# STM32WB30CEU6A register map
File version: 1.0
Registers are 32-bit, access not given, reset 0x0 unless marked. A register's access mark holds for its fields unless they carry their own. Offsets are from the block's base; [hi:lo] are bit positions; {n}, {i} and the like mark numbered series.

## GPIOE
Base 0x48001000
0x00 MODER
  [9:8] MODE4
0x04 OTYPER
  [4] OT4
0x08 OSPEEDR
  [9:8] OSPEED4
0x0C PUPDR
  [9:8] PUPD4
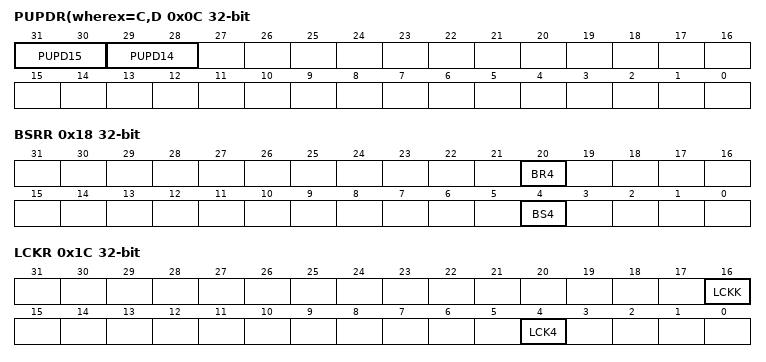
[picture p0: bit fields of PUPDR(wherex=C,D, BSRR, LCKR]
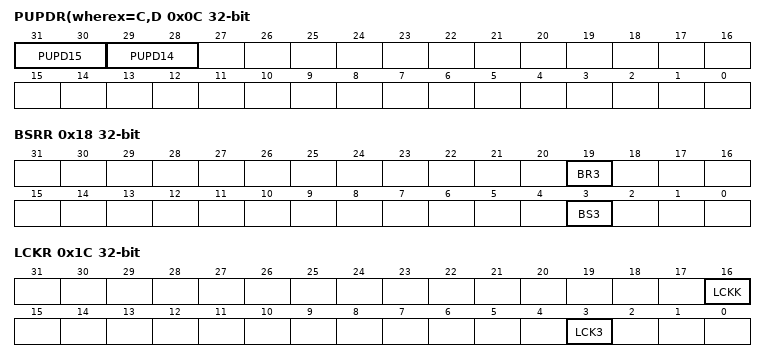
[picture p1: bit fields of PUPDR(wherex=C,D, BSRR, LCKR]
0x0C PUPDR(wherex=C,D
  [31:30] PUPD15, [29:28] PUPD14
0x10 IDR
  [4] ID4
0x14 ODR
  [4] OD4
0x18 BSRR
  [20] BR4, [4] BS4
0x1C LCKR
  [16] LCKK, [4] LCK4
0x20 AFRL
  [19:16] AFSEL4
0x28 BRR
  [4] BR4

## GPIOH
Base 0x48001C00
0x00 MODER
  [7:6] MODE3
0x04 OTYPER
  [3] OT3
0x08 OSPEEDR
  [7:6] OSPEED3
0x0C PUPDR
  [7:6] PUPD3
0x0C PUPDR(wherex=C,D
  [31:30] PUPD15, [29:28] PUPD14
0x10 IDR
  [3] ID3
0x14 ODR
  [3] OD3
0x18 BSRR
  [19] BR3, [3] BS3
0x1C LCKR
  [16] LCKK, [3] LCK3
0x20 AFRL
  [15:12] AFSEL3
0x28 BRR
  [3] BR3

## ADC
Base 0x50040000
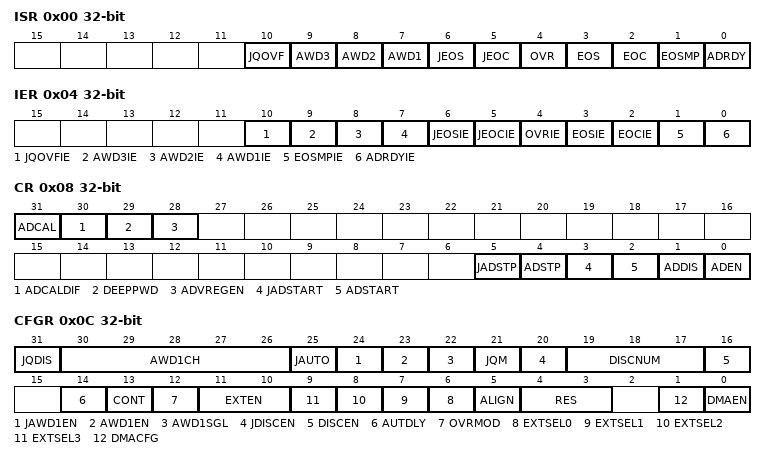
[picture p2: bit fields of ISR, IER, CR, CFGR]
0x00 ISR
  [10] JQOVF, [9] AWD3, [8] AWD2, [7] AWD1, [6] JEOS, [5] JEOC, [4] OVR, [3] EOS, [2] EOC, [1] EOSMP, [0] ADRDY
0x04 IER
  [10] JQOVFIE, [9] AWD3IE, [8] AWD2IE, [7] AWD1IE, [6] JEOSIE, [5] JEOCIE, [4] OVRIE, [3] EOSIE, [2] EOCIE, [1] EOSMPIE, [0] ADRDYIE
0x08 CR
  [31] ADCAL, [30] ADCALDIF, [29] DEEPPWD, [28] ADVREGEN, [5] JADSTP, [4] ADSTP, [3] JADSTART, [2] ADSTART, [1] ADDIS, [0] ADEN
0x0C CFGR
  [31] JQDIS, [30:26] AWD1CH, [25] JAUTO, [24] JAWD1EN, [23] AWD1EN, [22] AWD1SGL, [21] JQM, [20] JDISCEN, [19:17] DISCNUM, [16] DISCEN, [14] AUTDLY, [13] CONT, [12] OVRMOD, [11:10] EXTEN, [n+6] EXTSEL{n} (n=0..3), [5] ALIGN, [4:3] RES, [1] DMACFG, [0] DMAEN
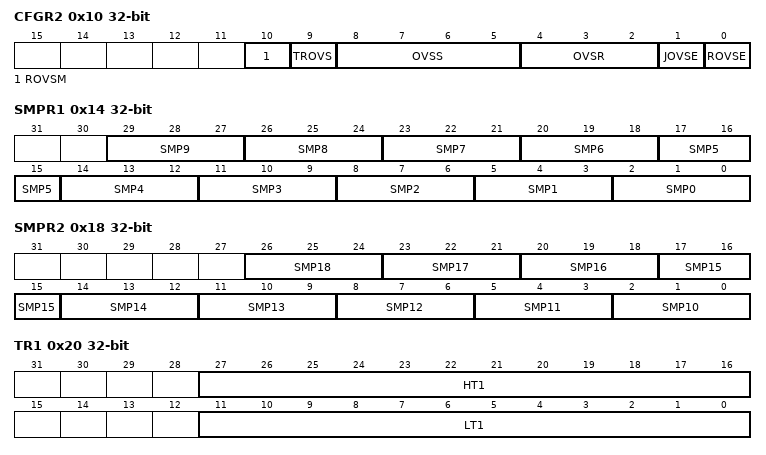
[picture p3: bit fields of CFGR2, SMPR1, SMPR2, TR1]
0x10 CFGR2
  [10] ROVSM, [9] TROVS, [8:5] OVSS, [4:2] OVSR, [1] JOVSE, [0] ROVSE
0x14 SMPR1
  [3n+2:3n] SMP{n} (n=0..9)
0x18 SMPR2
  [3n-28:3n-30] SMP{n} (n=10..18)
0x20 TR1
  [27:16] HT1, [11:0] LT1
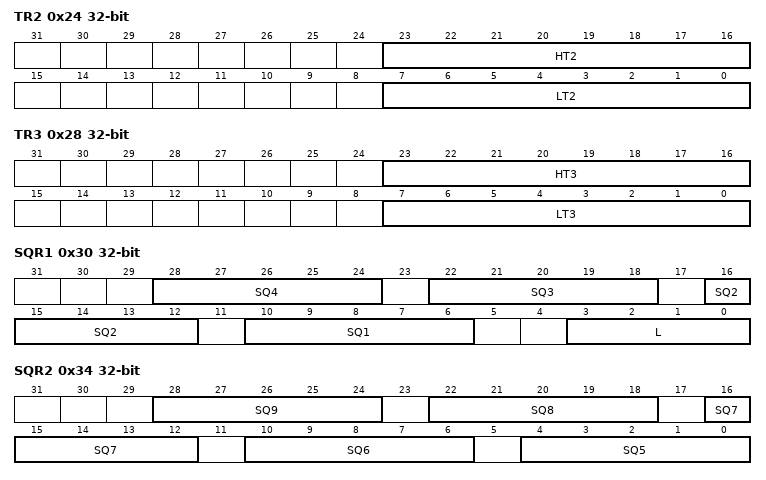
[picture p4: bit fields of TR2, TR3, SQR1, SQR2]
0x24 TR2
  [23:16] HT2, [7:0] LT2
0x28 TR3
  [23:16] HT3, [7:0] LT3
0x30 SQR1
  [6n+4:6n] SQ{n} (n=1..4), [3:0] L
0x34 SQR2
  [6n-26:6n-30] SQ{n} (n=5..9)
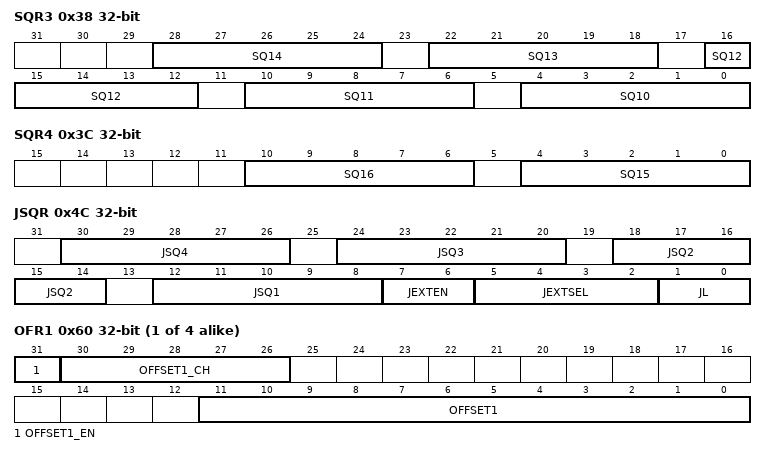
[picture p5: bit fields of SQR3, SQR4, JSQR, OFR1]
0x38 SQR3
  [6n-56:6n-60] SQ{n} (n=10..14)
0x3C SQR4
  [10:6] SQ16, [4:0] SQ15
0x40 DR
  [15:0] RDATA
0x4C JSQR
  [6n+6:6n+2] JSQ{n} (n=1..4), [7:6] JEXTEN, [5:2] JEXTSEL, [1:0] JL
{0x5C+4i} OFR{i} (i=1..4)
  [31] OFFSET{i}_EN, [30:26] OFFSET{i}_CH, [11:0] OFFSET{i}
{0x7C+4i} JDR{i} (i=1..4)
  [15:0] JDATA{i}
0xA0 AWD2CR
  [18:0] AWD2CH
0xA4 AWD3CR
  [18:0] AWD3CH
0xB0 DIFSEL
  [18:0] DIFSEL
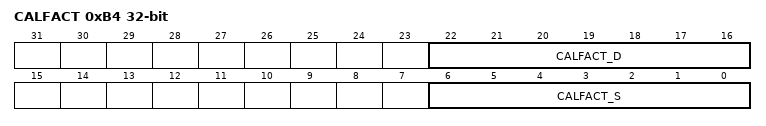
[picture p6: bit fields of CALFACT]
0xB4 CALFACT
  [22:16] CALFACT_D, [6:0] CALFACT_S

## PWR
Base 0x58000400
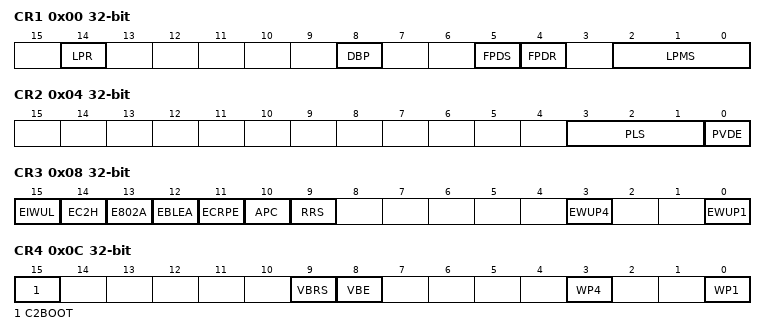
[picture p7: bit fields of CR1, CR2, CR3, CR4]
0x00 CR1
  [14] LPR, [8] DBP, [5] FPDS, [4] FPDR, [2:0] LPMS
0x04 CR2
  [3:1] PLS, [0] PVDE
0x08 CR3
  [15] EIWUL, [14] EC2H, [13] E802A, [12] EBLEA, [11] ECRPE, [10] APC, [9] RRS, [3] EWUP4, [0] EWUP1
0x0C CR4
  [15] C2BOOT, [9] VBRS, [8] VBE, [3] WP4, [0] WP1
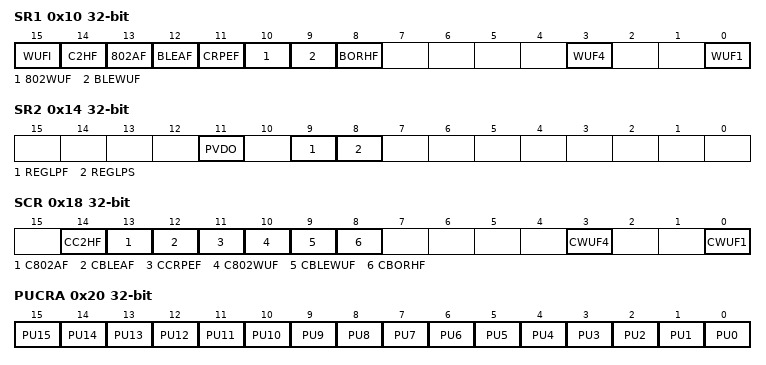
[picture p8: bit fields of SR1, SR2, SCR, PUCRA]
0x10 SR1
  [15] WUFI, [14] C2HF, [13] 802AF, [12] BLEAF, [11] CRPEF, [10] 802WUF, [9] BLEWUF, [8] BORHF, [3] WUF4, [0] WUF1
0x14 SR2
  [11] PVDO, [9] REGLPF, [8] REGLPS
0x18 SCR
  [14] CC2HF, [13] C802AF, [12] CBLEAF, [11] CCRPEF, [10] C802WUF, [9] CBLEWUF, [8] CBORHF, [3] CWUF4, [0] CWUF1
0x20 PUCRA
  [n] PU{n} (n=0..15)
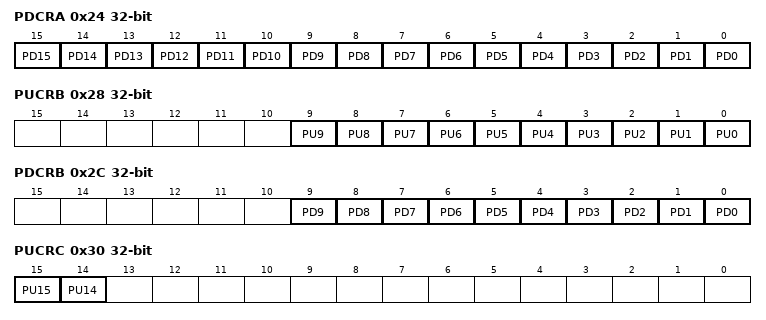
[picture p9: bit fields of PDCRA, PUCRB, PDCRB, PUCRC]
0x24 PDCRA
  [n] PD{n} (n=0..15)
0x28 PUCRB
  [n] PU{n} (n=0..9)
0x2C PDCRB
  [n] PD{n} (n=0..9)
0x30 PUCRC
  [15] PU15, [14] PU14
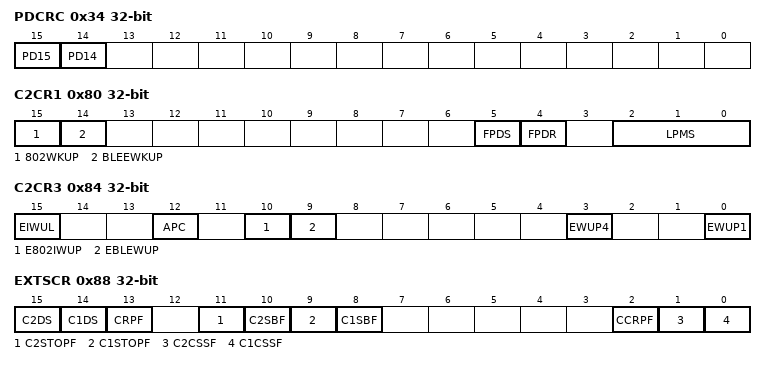
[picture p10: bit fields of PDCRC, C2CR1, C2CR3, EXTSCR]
0x34 PDCRC
  [15] PD15, [14] PD14
0x40 PUCRE
  [4] PU4
0x44 PDCRE
  [4] PD4
0x58 PUCRH
  [3] PU3
0x5C PDCRH
  [3] PD3
0x80 C2CR1
  [15] 802WKUP, [14] BLEEWKUP, [5] FPDS, [4] FPDR, [2:0] LPMS
0x84 C2CR3
  [15] EIWUL, [12] APC, [10] E802IWUP, [9] EBLEWUP, [3] EWUP4, [0] EWUP1
0x88 EXTSCR
  [15] C2DS, [14] C1DS, [13] CRPF, [11] C2STOPF, [10] C2SBF, [9] C1STOPF, [8] C1SBF, [2] CCRPF, [1] C2CSSF, [0] C1CSSF

## EXTI
Base 0x58000800
0x00 RTSR1
  [19:0] RT
0x04 FTSR1
  [19:0] FT
0x08 SWIER1
  [19:0] SW
0x0C RPR1
  [19:0] PIF
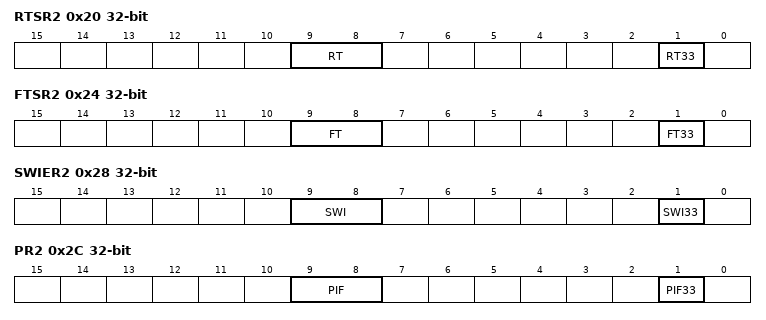
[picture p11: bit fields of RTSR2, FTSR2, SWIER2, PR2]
0x20 RTSR2
  [9:8] RT, [1] RT33
0x24 FTSR2
  [9:8] FT, [1] FT33
0x28 SWIER2
  [9:8] SWI, [1] SWI33
0x2C PR2
  [9:8] PIF, [1] PIF33
0x80 IMR1
  [24] IM24, [22] IM22, [30:0] IM
0x84 EMR1
  [19:0] EM
0x90 IMR2
  [16:1] IM
0x94 EMR2
  [9:8] EM
0xC0 C2IMR1
  [24] IM24, [22] IM22, [30:0] IM
0xC4 C2EMR1
  [19:0] EM
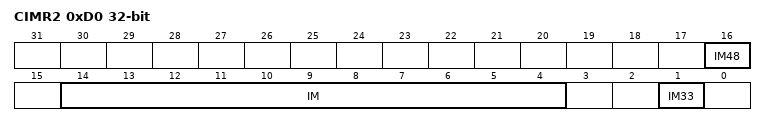
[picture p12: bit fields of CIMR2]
0xD0 CIMR2
  [16] IM48, [14:4] IM, [1] IM33
0xD4 C2EMR2
  [9:8] EM

## IPCC
Base 0x58000C00
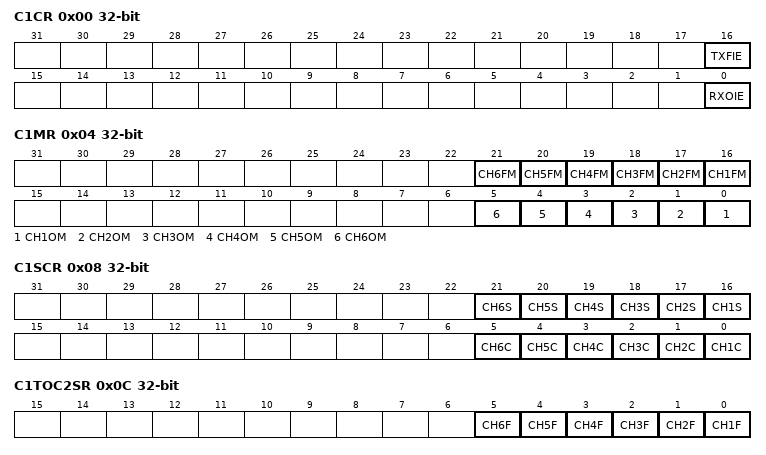
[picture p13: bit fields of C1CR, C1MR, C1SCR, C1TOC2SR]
0x00 C1CR
  [16] TXFIE, [0] RXOIE
0x04 C1MR
  [n+15] CH{n}FM (n=1..6), [n-1] CH{n}OM (n=1..6)
0x08 C1SCR
  [n+15] CH{n}S (n=1..6), [n-1] CH{n}C (n=1..6)
0x0C C1TOC2SR
  [n-1] CH{n}F (n=1..6)
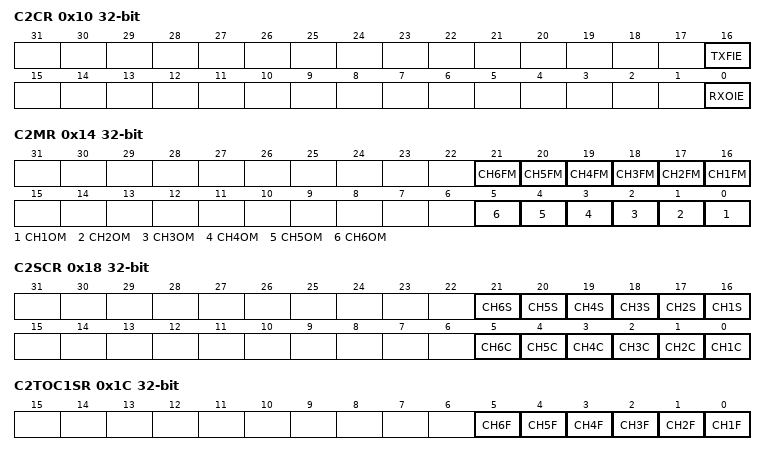
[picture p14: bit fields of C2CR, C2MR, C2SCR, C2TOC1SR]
0x10 C2CR
  [16] TXFIE, [0] RXOIE
0x14 C2MR
  [n+15] CH{n}FM (n=1..6), [n-1] CH{n}OM (n=1..6)
0x18 C2SCR
  [n+15] CH{n}S (n=1..6), [n-1] CH{n}C (n=1..6)
0x1C C2TOC1SR
  [n-1] CH{n}F (n=1..6)

## TRNG
Base 0x58001000
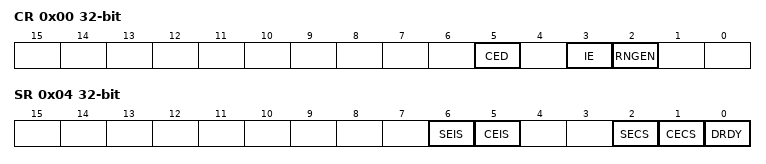
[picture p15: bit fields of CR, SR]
0x00 CR
  [5] CED, [3] IE, [2] RNGEN
0x04 SR
  [6] SEIS, [5] CEIS, [2] SECS, [1] CECS, [0] DRDY
0x08 DR
  [31:0] RNDATA

## HSEM
Base 0x58001400
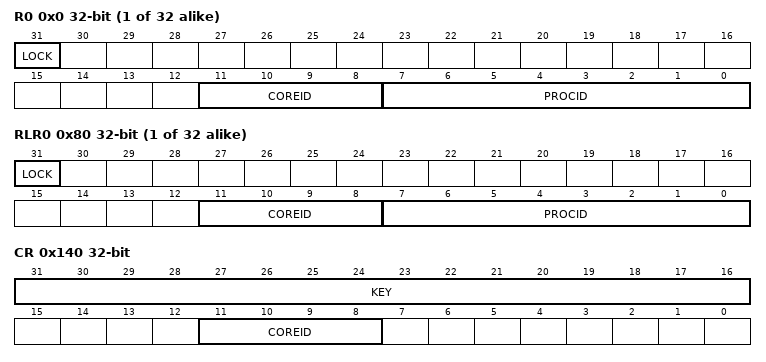
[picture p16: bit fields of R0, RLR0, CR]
{0x0+4i} R{i} (i=0..31)
  [31] LOCK, [11:8] COREID, [7:0] PROCID
{0x80+4i} RLR{i} (i=0..31)
  [31] LOCK, [11:8] COREID, [7:0] PROCID
0x100 C1IER
  [31:0] ISE
0x104 C1ICR
  [31:0] ISC
0x108 C1ISR
  [31:0] ISF
0x10C C1MISR
  [31:0] MISF
0x110 C2IER
  [31:0] ISE
0x114 C2ICR
  [31:0] ISC
0x118 C2ISR
  [31:0] ISF
0x11C C2MISR
  [31:0] MISF
0x140 CR
  [31:16] KEY, [11:8] COREID
0x144 KEYR
  [31:16] KEY

## AES2
Base 0x58001800
0x00 CR
  [23:20] NPBLB, [18] KEYSIZE, [14:13] GCMPH, [12] DMAOUTEN, [11] DMAINEN, [10] ERRIE, [9] CCFIE, [8] ERRC, [7] CCFC, [16:5] CHMOD, [4:3] MODE, [2:1] DATATYPE, [0] EN
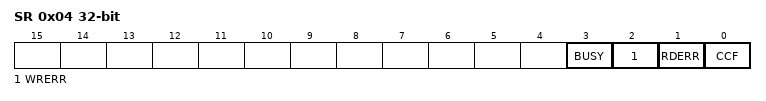
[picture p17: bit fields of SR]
0x04 SR
  [3] BUSY, [2] WRERR, [1] RDERR, [0] CCF
0x08 DINR
  [31:0] DIN
0x0C DOUTR
  [31:0] DOUT
{0x10+4i} KEYR{i} (i=0..3)
  [31:0] KEY
{0x20+4i} IVR{i} (i=0..3)
  [31:0] IVI
{0x20+4i} KEYR{i} (i=4..7)
  [31:0] KEY
{0x40+4i} SUSP{i}R (i=0..7)
  [31:0] SUSP

## PKA
Base 0x58002000
Same registers: PKARAM 0x58002400
0x00 CR
  [20] ADDRERRIE, [19] RAMERRIE, [17] PROCENDIE, [13:8] MODE, [1] START, [0] EN
0x04 SR
  [20] ADDRERRF, [19] RAMERRF, [17] PROCENDF, [16] BUSY
0x08 CLRFR
  [20] ADDRERRFC, [19] RAMERRFC, [17] PROCENDFC
